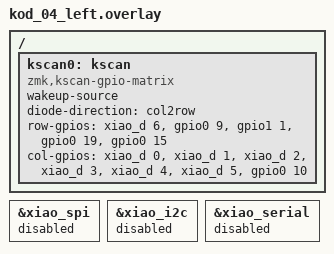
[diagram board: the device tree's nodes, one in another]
/*
 * Copyright (c) 2024 kodomari
 * SPDX-License-Identifier: MIT
 */

#include "kod_04.dtsi"

&xiao_spi { status = "disabled"; };
&xiao_i2c { status = "disabled"; };
&xiao_serial { status = "disabled"; };

/ {
    kscan0: kscan {
        compatible = "zmk,kscan-gpio-matrix";
        wakeup-source;
        diode-direction = "col2row";

        // 5行
        row-gpios
          = <&xiao_d 6  (GPIO_ACTIVE_HIGH | GPIO_PULL_DOWN)>   // D6
          , <&gpio0 9   (GPIO_ACTIVE_HIGH | GPIO_PULL_DOWN)>   // P0.09
          , <&gpio1 1   (GPIO_ACTIVE_HIGH | GPIO_PULL_DOWN)>   // P1.01
          , <&gpio0 19  (GPIO_ACTIVE_HIGH | GPIO_PULL_DOWN)>   // P0.19
          , <&gpio0 15  (GPIO_ACTIVE_HIGH | GPIO_PULL_DOWN)>   // P0.15
          ;

        // 7列
        col-gpios
          = <&xiao_d 0  GPIO_ACTIVE_HIGH>   // D0
          , <&xiao_d 1  GPIO_ACTIVE_HIGH>   // D1
          , <&xiao_d 2  GPIO_ACTIVE_HIGH>   // D2
          , <&xiao_d 3  GPIO_ACTIVE_HIGH>   // D3
          , <&xiao_d 4  GPIO_ACTIVE_HIGH>   // D4
          , <&xiao_d 5  GPIO_ACTIVE_HIGH>   // D5
          , <&gpio0 10  GPIO_ACTIVE_HIGH>   // P0.10
          ;
    };
};
